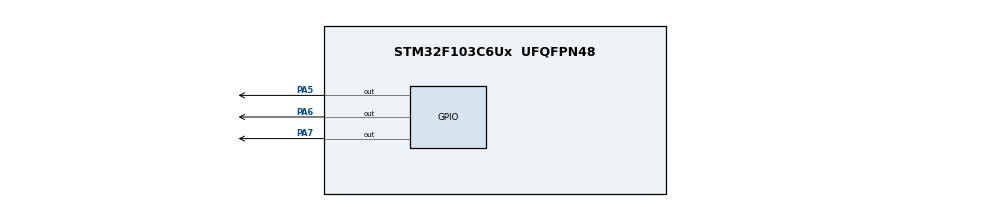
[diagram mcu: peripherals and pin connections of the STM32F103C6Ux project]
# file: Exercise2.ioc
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Mcu.Family=STM32F1
Mcu.Name=STM32F103C6Ux
Mcu.Package=UFQFPN48
NVIC.PriorityGroup=NVIC_PRIORITYGROUP_4
PA5.Signal=GPIO_Output
PA6.Signal=GPIO_Output
PA7.Signal=GPIO_Output
ProjectManager.HeapSize=0x200
ProjectManager.StackSize=0x400
ProjectManager.TargetToolchain=STM32CubeIDE
RCC.APB1Freq_Value=8000000
RCC.APB2Freq_Value=8000000
board=custom

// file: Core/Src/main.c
/* USER CODE BEGIN Header */
/**
  ******************************************************************************
  * @file           : main.c
  * @brief          : Main program body
  ******************************************************************************
  * @attention
  *
  * Copyright (c) 2025 STMicroelectronics.
  * All rights reserved.
  *
  * This software is licensed under terms that can be found in the LICENSE file
  * in the root directory of this software component.
  * If no LICENSE file comes with this software, it is provided AS-IS.
  *
  ******************************************************************************
  */
/* USER CODE END Header */
#include "main.h"

void SystemClock_Config(void);
/* USER CODE BEGIN PFP */
void MX_GPIO_Init(void);
/* USER CODE END PFP */

int main(void)
{

  /* MCU Configuration--------------------------------------------------------*/

  /* Reset of all peripherals, Initializes the Flash interface and the Systick. */
  HAL_Init();

  /* Configure the system clock */
  SystemClock_Config();

  /* Initialize all configured peripherals */
  /* USER CODE BEGIN 2 */
  MX_GPIO_Init();
  /* USER CODE END 2 */
  /* Infinite loop */
  while (1)
  {
    HAL_GPIO_WritePin(GPIOA, GPIO_PIN_5, RESET);
    HAL_GPIO_WritePin(GPIOA, GPIO_PIN_6 | GPIO_PIN_7, SET);
    HAL_Delay(5000);
    HAL_GPIO_WritePin(GPIOA, GPIO_PIN_6, RESET);
    HAL_GPIO_WritePin(GPIOA, GPIO_PIN_5 | GPIO_PIN_7, SET);
    HAL_Delay(2000);
    HAL_GPIO_WritePin(GPIOA, GPIO_PIN_7, RESET);
    HAL_GPIO_WritePin(GPIOA, GPIO_PIN_6 | GPIO_PIN_5, SET);
    HAL_Delay(3000);
  }
}

void SystemClock_Config(void)
{
  RCC_OscInitTypeDef RCC_OscInitStruct = {0};
  RCC_ClkInitTypeDef RCC_ClkInitStruct = {0};

  /** Initializes the RCC Oscillators according to the specified parameters
  * in the RCC_OscInitTypeDef structure.
  */
  RCC_OscInitStruct.OscillatorType = RCC_OSCILLATORTYPE_HSI;
  RCC_OscInitStruct.HSIState = RCC_HSI_ON;
  RCC_OscInitStruct.HSICalibrationValue = RCC_HSICALIBRATION_DEFAULT;
  RCC_OscInitStruct.PLL.PLLState = RCC_PLL_NONE;
  if (HAL_RCC_OscConfig(&RCC_OscInitStruct) != HAL_OK)
  {
    Error_Handler();
  }

  /** Initializes the CPU, AHB and APB buses clocks
  */
  RCC_ClkInitStruct.ClockType = RCC_CLOCKTYPE_HCLK|RCC_CLOCKTYPE_SYSCLK
                              |RCC_CLOCKTYPE_PCLK1|RCC_CLOCKTYPE_PCLK2;
  RCC_ClkInitStruct.SYSCLKSource = RCC_SYSCLKSOURCE_HSI;
  RCC_ClkInitStruct.AHBCLKDivider = RCC_SYSCLK_DIV1;
  RCC_ClkInitStruct.APB1CLKDivider = RCC_HCLK_DIV1;
  RCC_ClkInitStruct.APB2CLKDivider = RCC_HCLK_DIV1;

  if (HAL_RCC_ClockConfig(&RCC_ClkInitStruct, FLASH_LATENCY_0) != HAL_OK)
  {
    Error_Handler();
  }
}

/* USER CODE BEGIN 4 */
void MX_GPIO_Init(void){
  __HAL_RCC_GPIOA_CLK_ENABLE();
  GPIO_InitTypeDef init = {0};
  init.Mode = GPIO_MODE_OUTPUT_PP;
  init.Pin = GPIO_PIN_5 | GPIO_PIN_6 | GPIO_PIN_7;
  init.Pull = GPIO_PULLDOWN;
  init.Speed = GPIO_SPEED_FREQ_MEDIUM;
  HAL_GPIO_Init(GPIOA, &init);
}
/* USER CODE END 4 */

void Error_Handler(void)
{
  __disable_irq();
  while (1)
  {
  }
}
